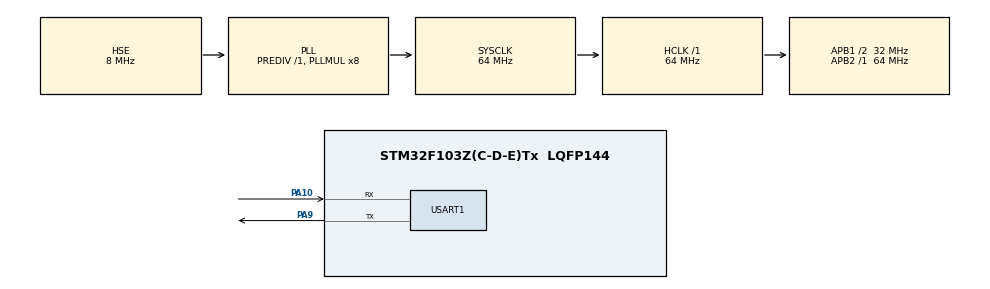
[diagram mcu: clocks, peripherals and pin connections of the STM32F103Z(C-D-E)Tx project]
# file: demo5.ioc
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Dma.Request0=USART1_RX
Dma.Request1=USART1_TX
Dma.USART1_RX.0.Direction=DMA_PERIPH_TO_MEMORY
Dma.USART1_RX.0.Instance=DMA1_Channel5
Dma.USART1_RX.0.MemDataAlignment=DMA_MDATAALIGN_BYTE
Dma.USART1_RX.0.MemInc=DMA_MINC_ENABLE
Dma.USART1_RX.0.Mode=DMA_NORMAL
Dma.USART1_RX.0.PeriphDataAlignment=DMA_PDATAALIGN_BYTE
Dma.USART1_RX.0.PeriphInc=DMA_PINC_DISABLE
Dma.USART1_RX.0.Priority=DMA_PRIORITY_LOW
Dma.USART1_TX.1.Direction=DMA_MEMORY_TO_PERIPH
Dma.USART1_TX.1.Instance=DMA1_Channel4
Dma.USART1_TX.1.MemDataAlignment=DMA_MDATAALIGN_BYTE
Dma.USART1_TX.1.MemInc=DMA_MINC_ENABLE
Dma.USART1_TX.1.Mode=DMA_NORMAL
Dma.USART1_TX.1.PeriphDataAlignment=DMA_PDATAALIGN_BYTE
Dma.USART1_TX.1.PeriphInc=DMA_PINC_DISABLE
Dma.USART1_TX.1.Priority=DMA_PRIORITY_LOW
Mcu.Family=STM32F1
Mcu.Name=STM32F103Z(C-D-E)Tx
Mcu.Package=LQFP144
NVIC.DMA1_Channel4_IRQn=true\:0\:0\:false\:false\:true\:false\:true\:true
NVIC.DMA1_Channel5_IRQn=true\:0\:0\:false\:false\:true\:false\:true\:true
NVIC.PriorityGroup=NVIC_PRIORITYGROUP_4
NVIC.USART1_IRQn=true\:0\:0\:false\:false\:true\:true\:true\:true
OSC_IN.Mode=HSE-External-Oscillator
OSC_IN.Signal=RCC_OSC_IN
OSC_OUT.Mode=HSE-External-Oscillator
OSC_OUT.Signal=RCC_OSC_OUT
PA10.Mode=Asynchronous
PA10.Signal=USART1_RX
PA9.Mode=Asynchronous
PA9.Signal=USART1_TX
PC14-OSC32_IN.Mode=LSE-External-Oscillator
PC14-OSC32_IN.Signal=RCC_OSC32_IN
PC15-OSC32_OUT.Mode=LSE-External-Oscillator
PC15-OSC32_OUT.Signal=RCC_OSC32_OUT
ProjectManager.HeapSize=0x200
ProjectManager.StackSize=0x400
ProjectManager.TargetToolchain=MDK-ARM V5
RCC.AHBFreq_Value=64000000
RCC.APB1CLKDivider=RCC_HCLK_DIV2
RCC.APB1Freq_Value=32000000
RCC.APB1TimFreq_Value=64000000
RCC.APB2Freq_Value=64000000
RCC.APB2TimFreq_Value=64000000
RCC.HCLKFreq_Value=64000000
RCC.PLLMUL=RCC_PLL_MUL8
RCC.PLLSourceVirtual=RCC_PLLSOURCE_HSE
RCC.SYSCLKFreq_VALUE=64000000
RCC.SYSCLKSource=RCC_SYSCLKSOURCE_PLLCLK
RCC.USBFreq_Value=64000000
USART1.VirtualMode=VM_ASYNC
VP_SYS_VS_ND.Mode=No_Debug
board=custom

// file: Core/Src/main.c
/* USER CODE BEGIN Header */
/**
  ******************************************************************************
  * @file           : main.c
  * @brief          : Main program body
  ******************************************************************************
  * @attention
  *
  * Copyright (c) 2023 STMicroelectronics.
  * All rights reserved.
  *
  * This software is licensed under terms that can be found in the LICENSE file
  * in the root directory of this software component.
  * If no LICENSE file comes with this software, it is provided AS-IS.
  *
  ******************************************************************************
  */
/* USER CODE END Header */
#include "main.h"
#include "dma.h"
#include "usart.h"
#include "gpio.h"

/* USER CODE BEGIN Includes */
#include <stdio.h>
#include <stdbool.h>
/* USER CODE END Includes */

/* USER CODE BEGIN PV */
extern uint8_t rx_len;
extern uint8_t recv_end_flag;
extern uint8_t rx_buffer[200];
extern uint8_t tx_buffer[200];
/* USER CODE END PV */

void SystemClock_Config(void);

int main(void)
{

  /* MCU Configuration--------------------------------------------------------*/

  /* Reset of all peripherals, Initializes the Flash interface and the Systick. */
  HAL_Init();

  /* Configure the system clock */
  SystemClock_Config();

  /* Initialize all configured peripherals */
  MX_GPIO_Init();
  MX_DMA_Init();
  MX_USART1_UART_Init();
  /* USER CODE BEGIN 2 */
	printf("UART_IDLE_DMA\r\n");
	__HAL_UART_ENABLE_IT(&huart1, UART_IT_IDLE);
	while(__HAL_UART_GET_FLAG(&huart1,UART_FLAG_IDLE));
	//开启DMA
	HAL_UART_Receive_DMA(&huart1,rx_buffer,sizeof(rx_buffer));
	recv_end_flag=0;
	rx_len = 0;
	printf("接收不定长数据！\r\n");

	HAL_Delay(1000);
  /* USER CODE END 2 */

  /* Infinite loop */
  /* USER CODE BEGIN WHILE */
  while (1)
  {
		if(recv_end_flag ==1)
		{
			printf("接收到的数据长度为%d\r\n",rx_len);

			//HAL_UART_Transmit(&huart1, tx_buffer, rx_len, 100);
			MY_UART_Transmit(tx_buffer,rx_len);
			for(uint8_t i=0;i<rx_len;i++)
			{
				rx_buffer[i]=0;
				tx_buffer[i]=0;
			}
			rx_len=0;
			recv_end_flag=0;
		}
    /* USER CODE END WHILE */

  }
}

void SystemClock_Config(void)
{
  RCC_OscInitTypeDef RCC_OscInitStruct = {0};
  RCC_ClkInitTypeDef RCC_ClkInitStruct = {0};

  /** Initializes the RCC Oscillators according to the specified parameters
  * in the RCC_OscInitTypeDef structure.
  */
  RCC_OscInitStruct.OscillatorType = RCC_OSCILLATORTYPE_HSE;
  RCC_OscInitStruct.HSEState = RCC_HSE_ON;
  RCC_OscInitStruct.HSEPredivValue = RCC_HSE_PREDIV_DIV1;
  RCC_OscInitStruct.HSIState = RCC_HSI_ON;
  RCC_OscInitStruct.PLL.PLLState = RCC_PLL_ON;
  RCC_OscInitStruct.PLL.PLLSource = RCC_PLLSOURCE_HSE;
  RCC_OscInitStruct.PLL.PLLMUL = RCC_PLL_MUL8;
  if (HAL_RCC_OscConfig(&RCC_OscInitStruct) != HAL_OK)
  {
    Error_Handler();
  }

  /** Initializes the CPU, AHB and APB buses clocks
  */
  RCC_ClkInitStruct.ClockType = RCC_CLOCKTYPE_HCLK|RCC_CLOCKTYPE_SYSCLK
                              |RCC_CLOCKTYPE_PCLK1|RCC_CLOCKTYPE_PCLK2;
  RCC_ClkInitStruct.SYSCLKSource = RCC_SYSCLKSOURCE_PLLCLK;
  RCC_ClkInitStruct.AHBCLKDivider = RCC_SYSCLK_DIV1;
  RCC_ClkInitStruct.APB1CLKDivider = RCC_HCLK_DIV2;
  RCC_ClkInitStruct.APB2CLKDivider = RCC_HCLK_DIV1;

  if (HAL_RCC_ClockConfig(&RCC_ClkInitStruct, FLASH_LATENCY_2) != HAL_OK)
  {
    Error_Handler();
  }
}

void Error_Handler(void)
{
  __disable_irq();
  while (1)
  {
  }
}
